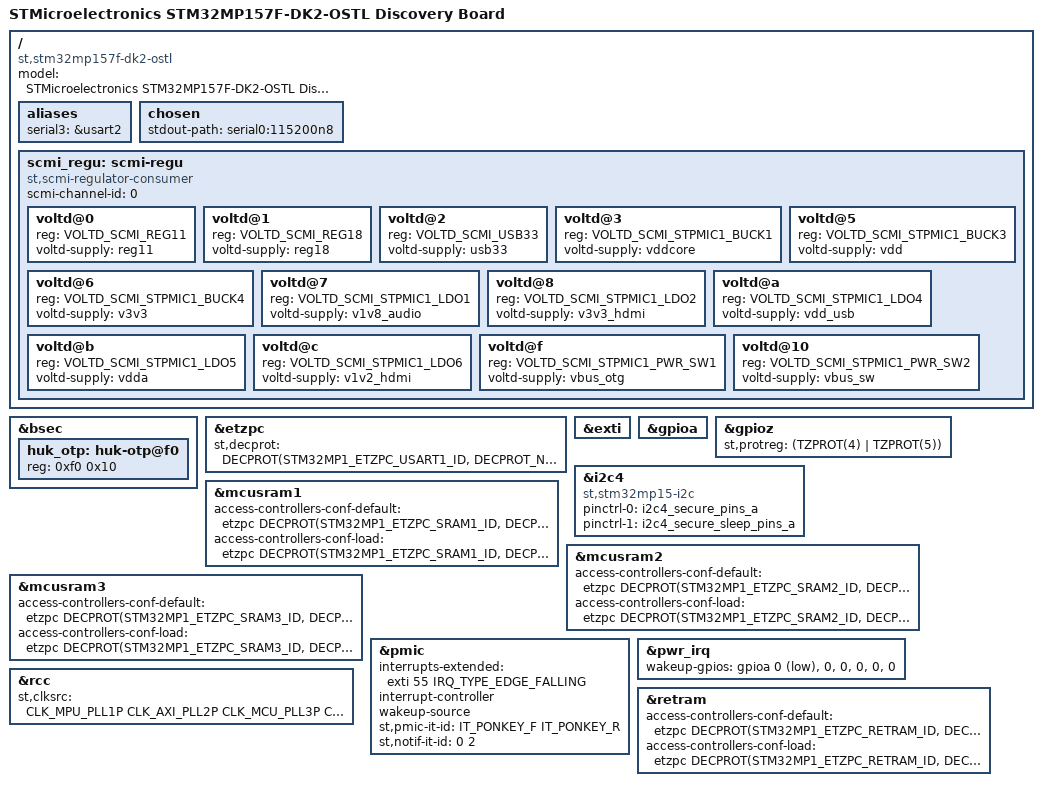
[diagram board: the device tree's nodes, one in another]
// SPDX-License-Identifier: (GPL-2.0-only OR BSD-3-Clause)
/*
 * Copyright (C) STMicroelectronics 2025 - All Rights Reserved
 * Author: Alexandre Torgue <alexandre.torgue@st.com> for STMicroelectronics.
 * Author: Pascal Paillet <p.paillet@st.com> for STMicroelectronics.
 */

/dts-v1/;

#include "stm32mp157.dtsi"
#include "stm32mp15xf.dtsi"
#include "stm32mp15-pinctrl.dtsi"
#include "stm32mp15xxac-pinctrl.dtsi"
#include "stm32mp15xx-dkx.dtsi"

#include <dt-bindings/gpio/stm32mp_gpio.h>
#include <dt-bindings/regulator/st,stm32mp15-regulator.h>

/ {
	model = "STMicroelectronics STM32MP157F-DK2-OSTL Discovery Board";
	compatible = "st,stm32mp157f-dk2-ostl", "st,stm32mp157f-dk2", "st,stm32mp157";

	aliases {
		serial3 = &usart2;
	};

	chosen {
		stdout-path = "serial0:115200n8";
	};

	scmi_regu: scmi-regu {
		compatible = "st,scmi-regulator-consumer";
		#address-cells = <1>;
		#size-cells = <0>;

		scmi-channel-id = <0>;

		voltd@0 {
			reg = <VOLTD_SCMI_REG11>;
			voltd-supply = <&reg11>;
		};

		voltd@1 {
			reg = <VOLTD_SCMI_REG18>;
			voltd-supply = <&reg18>;
		};

		voltd@2 {
			reg = <VOLTD_SCMI_USB33>;
			voltd-supply = <&usb33>;
		};

		voltd@3 {
			reg = <VOLTD_SCMI_STPMIC1_BUCK1>;
			voltd-supply = <&vddcore>;
		};

		voltd@5 {
			reg = <VOLTD_SCMI_STPMIC1_BUCK3>;
			voltd-supply = <&vdd>;
		};

		voltd@6 {
			reg = <VOLTD_SCMI_STPMIC1_BUCK4>;
			voltd-supply = <&v3v3>;
		};

		voltd@7 {
			reg = <VOLTD_SCMI_STPMIC1_LDO1>;
			voltd-supply = <&v1v8_audio>;
		};

		voltd@8 {
			reg = <VOLTD_SCMI_STPMIC1_LDO2>;
			voltd-supply = <&v3v3_hdmi>;
		};

		voltd@a {
			reg = <VOLTD_SCMI_STPMIC1_LDO4>;
			voltd-supply = <&vdd_usb>;
		};

		voltd@b {
			reg = <VOLTD_SCMI_STPMIC1_LDO5>;
			voltd-supply = <&vdda>;
		};

		voltd@c {
			reg = <VOLTD_SCMI_STPMIC1_LDO6>;
			voltd-supply = <&v1v2_hdmi>;
		};

		voltd@f {
			reg = <VOLTD_SCMI_STPMIC1_PWR_SW1>;
			voltd-supply = <&vbus_otg>;
		};

		voltd@10 {
			reg = <VOLTD_SCMI_STPMIC1_PWR_SW2>;
			voltd-supply = <&vbus_sw>;
		};
	};
};

&bsec {
	huk_otp: huk-otp@f0 {
		reg = <0xf0 0x10>;
	};
};

&etzpc {
	st,decprot = <
		DECPROT(STM32MP1_ETZPC_USART1_ID, DECPROT_NS_RW, DECPROT_UNLOCK)
		DECPROT(STM32MP1_ETZPC_SPI6_ID, DECPROT_NS_RW, DECPROT_UNLOCK)
		DECPROT(STM32MP1_ETZPC_I2C4_ID, DECPROT_S_RW, DECPROT_LOCK)
		DECPROT(STM32MP1_ETZPC_I2C6_ID, DECPROT_NS_RW, DECPROT_UNLOCK)
		DECPROT(STM32MP1_ETZPC_RNG1_ID, DECPROT_S_RW, DECPROT_UNLOCK)
		DECPROT(STM32MP1_ETZPC_HASH1_ID, DECPROT_NS_RW, DECPROT_UNLOCK)
		DECPROT(STM32MP1_ETZPC_CRYP1_ID, DECPROT_NS_RW, DECPROT_UNLOCK)
		DECPROT(STM32MP1_ETZPC_DDRCTRL_ID, DECPROT_NS_R_S_W, DECPROT_LOCK)
		DECPROT(STM32MP1_ETZPC_DDRPHYC_ID, DECPROT_NS_R_S_W, DECPROT_LOCK)
		DECPROT(STM32MP1_ETZPC_STGENC_ID, DECPROT_S_RW, DECPROT_LOCK)
		DECPROT(STM32MP1_ETZPC_BKPSRAM_ID, DECPROT_S_RW, DECPROT_LOCK)
		DECPROT(STM32MP1_ETZPC_IWDG1_ID, DECPROT_S_RW, DECPROT_LOCK)
	>;
};

&exti {
	status = "okay";
};

&gpioa {
	status = "okay";
};

&gpioz {
	st,protreg = <(TZPROT(4) | TZPROT(5))>;
};

&i2c4 {
	compatible = "st,stm32mp15-i2c";
	pinctrl-names = "default", "sleep";
	pinctrl-0 = <&i2c4_secure_pins_a>;
	pinctrl-1 = <&i2c4_secure_sleep_pins_a>;
};

&mcusram1 {
	access-controllers-conf-default = <&etzpc DECPROT(STM32MP1_ETZPC_SRAM1_ID, DECPROT_MCU_ISOLATION, DECPROT_UNLOCK)>;
	access-controllers-conf-load = <&etzpc DECPROT(STM32MP1_ETZPC_SRAM1_ID, DECPROT_S_RW, DECPROT_UNLOCK)>;
};

&mcusram2 {
	access-controllers-conf-default = <&etzpc DECPROT(STM32MP1_ETZPC_SRAM2_ID, DECPROT_MCU_ISOLATION, DECPROT_UNLOCK)>;
	access-controllers-conf-load = <&etzpc DECPROT(STM32MP1_ETZPC_SRAM2_ID, DECPROT_S_RW, DECPROT_UNLOCK)>;
};

&mcusram3 {
	access-controllers-conf-default = <&etzpc DECPROT(STM32MP1_ETZPC_SRAM3_ID, DECPROT_NS_RW, DECPROT_UNLOCK)>;
	access-controllers-conf-load = <&etzpc DECPROT(STM32MP1_ETZPC_SRAM3_ID, DECPROT_S_RW, DECPROT_UNLOCK)>;
};

&pmic {
	interrupts-extended = <&exti 55 IRQ_TYPE_EDGE_FALLING>;
	interrupt-controller;
	#interrupt-cells = <2>;
	wakeup-source;

	st,pmic-it-id = <IT_PONKEY_F IT_PONKEY_R>;
	st,notif-it-id = <0 2>;
};

&pwr_irq {
	status = "okay";
	wakeup-gpios = <&gpioa 0 ((1<<31) | GPIO_ACTIVE_LOW | GPIO_PULL_UP)>,
	               <0>, <0>, <0>, <0>, <0>;
};

&rcc {
	st,clksrc = <
		CLK_MPU_PLL1P
		CLK_AXI_PLL2P
		CLK_MCU_PLL3P
		CLK_RTC_LSE
		CLK_MCO1_DISABLED
		CLK_MCO2_DISABLED
		CLK_CKPER_HSE
		CLK_FMC_ACLK
		CLK_QSPI_ACLK
		CLK_ETH_PLL4P
		CLK_SDMMC12_PLL4P
		CLK_DSI_DSIPLL
		CLK_STGEN_HSE
		CLK_USBPHY_HSE
		CLK_SPI2S1_PLL3Q
		CLK_SPI2S23_PLL3Q
		CLK_SPI45_HSI
		CLK_SPI6_HSI
		CLK_I2C46_HSI
		CLK_SDMMC3_PLL4P
		CLK_USBO_USBPHY
		CLK_ADC_CKPER
		CLK_CEC_LSE
		CLK_I2C12_HSI
		CLK_I2C35_HSI
		CLK_UART1_HSI
		CLK_UART24_HSI
		CLK_UART35_HSI
		CLK_UART6_HSI
		CLK_UART78_HSI
		CLK_SPDIF_PLL4P
		CLK_FDCAN_PLL4R
		CLK_SAI1_PLL3Q
		CLK_SAI2_PLL3Q
		CLK_SAI3_PLL3Q
		CLK_SAI4_PLL3Q
		CLK_RNG1_CSI
		CLK_RNG2_LSI
		CLK_LPTIM1_PCLK1
		CLK_LPTIM23_PCLK3
		CLK_LPTIM45_LSI
	>;
};

&retram {
	access-controllers-conf-default = <&etzpc DECPROT(STM32MP1_ETZPC_RETRAM_ID, DECPROT_MCU_ISOLATION, DECPROT_UNLOCK)>;
	access-controllers-conf-load = <&etzpc DECPROT(STM32MP1_ETZPC_RETRAM_ID, DECPROT_S_RW, DECPROT_UNLOCK)>;
};
